# M55M1 register map
File version: 1.0
Registers are 32-bit, read-write, reset 0x0 unless marked. A register's access mark holds for its fields unless they carry their own. Offsets are from the block's base; [hi:lo] are bit positions; {n}, {i} and the like mark numbered series; 'fields as' and 'values as' point back to an identical list.

## LPI2C0 — LPI2C Register Map
Base 0x40443000
Same registers: LPI2C0_NS 0x50443000
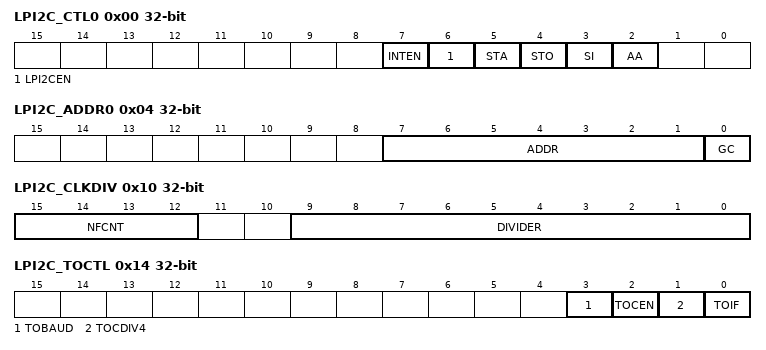
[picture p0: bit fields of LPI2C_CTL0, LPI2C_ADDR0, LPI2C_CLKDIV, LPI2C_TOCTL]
0x00 LPI2C_CTL0 — LPI2C Control Register 0
  [7] INTEN — Enable Interrupt
    0=LPI2C interrupt Disabled; 1=LPI2C interrupt Enabled
  [6] LPI2CEN — LPI2C Controller Enable Bit
    0=LPI2C controller Disabled; 1=LPI2C controller Enabled
  [5] STA — LPI2C START Control. Setting STA to logic 1 to enter Master mode, the LPI2C hardware sends a START or repeat START condition to bus when the bus is free. This bit will be cleared by hardware automatically.
  [4] STO — LPI2C STOP Control. In Master mode, set STO to transmit a STOP condition to bus then LPI2C controller will check the bus condition if a STOP condition is detected. This bit will be cleared by hardware automatically.
  [3] SI — LPI2C Interrupt Flag. When a new LPI2C state is present in the LPI2C_STATUS0 register, the SI flag is set by hardware. If bit INTEN (LPI2C_CTL0 [7]) is set, the LPI2C interrupt is requested. SI must be cleared by software. Clear SI by writing 1 to this bit.
  [2] AA — Assert Acknowledge Control
0x04 LPI2C_ADDR0 — LPI2C Slave Address Register0
  [7:1] ADDR — LPI2C Address. The content of this register is irrelevant when LPI2C is in Master mode. In the slave mode, the seven most significant bits must be loaded with the chip's own address. The LPI2C hardware will react if either of the address is matched. Note: When software set 7'h000, the address cannot be used.
  [0] GC — General Call Function
    0=General Call Function Disabled; 1=General Call Function Enabled
0x08 LPI2C_DAT — LPI2C Data Register
  [7:0] DAT — LPI2C Data. Bit [7:0] is located with the 8-bit transferred/received data of LPI2C serial port.
0x0C LPI2C_STATUS0 ro reset 0xF8 — LPI2C Status Register 0
  [7:0] STATUS — LPI2C Status
0x10 LPI2C_CLKDIV — LPI2C Clock Divided Register
  [15:12] NFCNT — Noise Filter Count. The register bits control the input filter width. If the pulse width is narrower than the setting((3+N)*PCLK), it will be ignored. Note: Filter width Min :3*PCLK, Max : 18*PCLK
    0=Filter width 3*PCLK; 1=Filter width 4*PCLK
  [9:0] DIVIDER — LPI2C Clock Divider. Note: The minimum value of DIVIDER is 4.
0x14 LPI2C_TOCTL — LPI2C Time-out Control Register
  [3] TOBAUD — Time-out Counter Input Clock Using Baud Rate Frequency. When enabled, the time-out counter is using baud rate.
    0=Time-out counter is using PCLK or PCLK/4; 1=Time-out counter is using IC baud rate
  [2] TOCEN — Time-out Counter Enable Bit. When enabled, the 14-bit time-out counter will start counting when SI is cleared. Setting flag SI to '1' will reset counter and re-start up counting after SI is cleared.
    0=Time-out counter Disabled; 1=Time-out counter Enabled
  [1] TOCDIV4 — Time-out Counter Input Clock Divided by 4. When enabled, the time-out period is extended 4 times. Note: This bit only worked when LPI2C_TOCTL[3] is set to 0.
    0=Time-out period is extend 4 times Disabled; 1=Time-out period is extend 4 times Enabled
  [0] TOIF — Time-out Flag. This bit is set by hardware when LPI2C time-out happened and it can interrupt CPU if LPI2C interrupt enable bit (INTEN) is set to 1. Note: Software can write 1 to clear this bit.
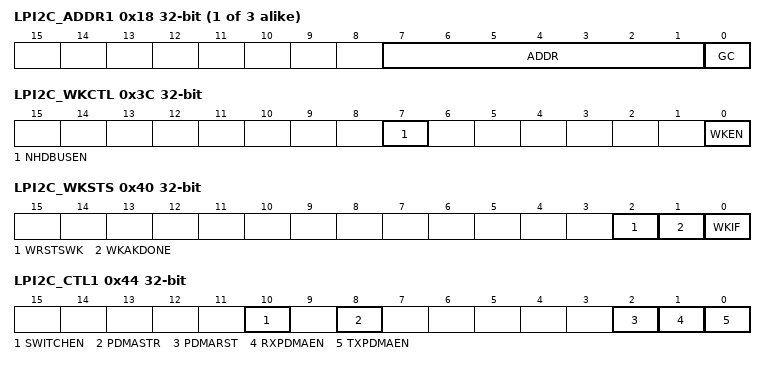
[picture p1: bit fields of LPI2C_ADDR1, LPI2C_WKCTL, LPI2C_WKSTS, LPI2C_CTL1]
{0x14+4i} LPI2C_ADDR{i} (i=1..3) — LPI2C Slave Address Register{i}
  fields as LPI2C_ADDR0
{0x24+4i} LPI2C_ADDRMSK{i} (i=0..3) — LPI2C Slave Address Mask Register{i}
  [7:1] ADDRMSK — LPI2C Address Mask. LPI2C bus controllers support multiple address recognition with four address mask register. When the bit in the address mask register is set to one, it means the received corresponding address bit is don't-care. If the bit is set to zero, that means the received corresponding register bit should be exact the same as address register.
    0=Mask Disabled (the received corresponding register bit should be exact the same as address register.); 1=Mask Enabled (the received corresponding address bit is don't care.)
0x3C LPI2C_WKCTL — LPI2C Wake-up Control Register
  [7] NHDBUSEN — LPI2C No Hold BUS Enable Bit. Note: The LPI2C controller could respond when WKIF event is not clear, it may cause error data transmitted or received. If data transmitted or received when WKIF event is not clear, user must reset LPI2C controller and execute the original operation again.
    0=LPI2C hold bus after wake-up; 1=LPI2C don't hold bus after wake-up
  [0] WKEN — LPI2C Wake-up Enable Bit. Note: This is for slave address match wakeup.
    0=LPI2C wake-up function Disabled; 1=LPI2C wake-up function Enabled
0x40 LPI2C_WKSTS — LPI2C Wake-up Status Register
  [2] WRSTSWK — Read/Write Status Bit in Address Wakeup Frame. Note: This bit will be cleared when software can write 1 to WKAKDONE bit.
    0=Write command be record on the address match wakeup frame; 1=Read command be record on the address match wakeup frame
  [1] WKAKDONE — Wakeup Address Frame Acknowledge Bit Done. Note: This bit can't release WKIF. Software can write 1 to clear this bit.
    0=The ACK bit cycle of address match frame isn't done; 1=The ACK bit cycle of address match frame is done in power-down
  [0] WKIF — LPI2C Wake-up Flag. When chip is woken up from Power-down mode by LPI2C, this bit is set to 1. Software can write 1 to clear this bit.
0x44 LPI2C_CTL1 — LPI2C Control Register 1
  [10] SWITCHEN — SCL And SDA Pin Switch Enable Bit. Note: Original pin configuration table is shown in Basic Configuration chapter.
    0=LPIC use original pin configuration; 1=LPIC switch SCL and SDA pin configuration
  [8] PDMASTR — LPPDMA Stretch Bit
    0=LPI2C send STOP automatically after LPPDMA transfer done. (only master TX); 1=LPI2C SCL bus is stretched by hardware after LPPDMA transfer done if the SI is not cleared. (only master TX)
  [2] PDMARST — LPPDMA Reset
    0=No effect; 1=Reset the LPI2C request to LPPDMA
  [1] RXPDMAEN — LPPDMA Receive Channel Available
    0=Receive LPPDMA function Disabled; 1=Receive LPPDMA function Enabled
  [0] TXPDMAEN — LPPDMA Transmit Channel Available
    0=Transmit LPPDMA function Disabled; 1=Transmit LPPDMA function Enabled
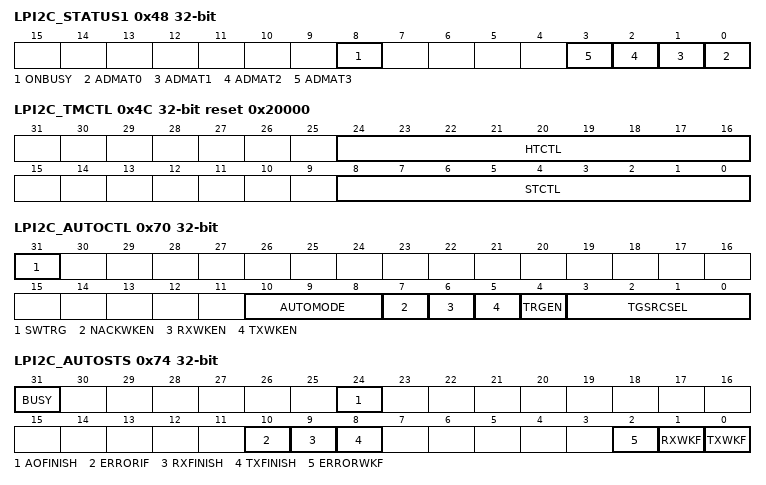
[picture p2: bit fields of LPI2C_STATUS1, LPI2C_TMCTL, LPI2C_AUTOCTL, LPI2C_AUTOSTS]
0x48 LPI2C_STATUS1 — LPI2C Status Register 1
  [8] ONBUSY ro — On Bus Busy (Read Only). Indicates that a communication is in progress on the bus. It is set by hardware when a START condition is detected. It is cleared by hardware when a STOP condition is detected.
    0=The bus is IDLE (both SCL and SDA High); 1=The bus is busy
  [n] ADMAT{n} (n=0..3) — LPI2C Address {n} Match Status. When address {n} is matched, hardware will inform which address used. This bit will set to 1, and software can write 1 to clear this bit.
0x4C LPI2C_TMCTL reset 0x20000 — LPI2C Timing Configure Control Register
  [24:16] HTCTL — Hold Time Configure Control. This field is used to generate the delay timing between SCL falling edge and SDA rising edge in transmission mode.
  [8:0] STCTL — Setup Time Configure Control. This field is used to generate a delay timing between SDA falling edge and SCL rising edge in transmission mode. Note: Setup time setting should not make SCL output less than three PCLKs.
0x70 LPI2C_AUTOCTL — LPI2C Automatic Operation Control Register
  [31] SWTRG — Auto-operation Mode Software Trigger Bit. Note: TGSRCSEL(LPI2C_AUTOCTL[3:0]) need to be set to 0x8 first. This bit will be cleared by hardware automatically.
    0=No operation; 1=Software trigger auto-operattion
  [10:8] AUTOMODE — Auto-operation Mode Select. Note: Use TXWKEN(LPI2C_AUTOCTL[5]) to wakeup system when using auto TXPDMA transfer mode AUTOMODE(LPI2C_AUTOCTL[10:8]) in power-down mode.
    0=No auto-operation; 1=Auto TXPDMA transfer mode; 2=Auto RXPDMA transfer mode; 3=Random Read mode, repeat start between TX/RX; 4=Random Read mode, stop and start between TX/RX
  [7] NACKWKEN — Receive Slave NACK Wakeup Enable bit
    0=Stop after receiving NACK; 1=Wakeup after receiving NACK
  [6] RXWKEN — RX Transfer Count Match Wakeup Enable bit
    0=Power off after RX transfer count matches RXCNT; 1=Wakeup after RX transfer count matches RXCNT
  [5] TXWKEN — TX Transfer Count Match Wakeup Enable bit
    0=Power off after TX transfer count matches TXCNT; 1=Wakeup after TX transfer count matches TXCNT
  [4] TRGEN — Trigger Source Enable bit
    0=LPIC trigger source disable; 1=LPIC trigger source enable
  [3:0] TGSRCSEL — Low Power Auto-operation Trigger Source Select
    0=Low Power Auto-operation Trigger Source from LPTMR0; 1=Low Power Auto-operation Trigger Source from LPTMR1; 2=Low Power Auto-operation Trigger Source from TTMR0; 3=Low Power Auto-operation Trigger Source from TTMR1; 4=Low Power Auto-operation Trigger Source from WKIOA0(GPA0); 5=Low Power Auto-operation Trigger Source from WKIOB0(GPB0); 6=Low Power Auto-operation Trigger Source from WKIOC0(GPC0); 7=Low Power Auto-operation Trigger Source from WKIOD0(GPD0); 8=Low Power Auto-operation Trigger Source from Software setting SWTRG(LPI2C_AUTOCTL[31]) to 1
0x74 LPI2C_AUTOSTS — LPI2C Automatic Operation Status Register
  [31] BUSY — Busy Flag. When chip is woken up and this bit is set to 1. It means that there were one or more requests from trigger source during transfer. Software can write 1 to clear this bit.
  [24] AOFINISH — Automatic Operation Finish Flag. AOFINISH is set when finishing one round of auto operation, but it will not issue interrupt. Software can write 1 to clear this bit.
  [10] ERRORIF — ERROR Interrupt Flag. When LPI2C receiving NACK from slave, running into bus error or arbitration lost, this bit is set to 1. Software can write 1 to clear this bit.
  [9] RXFINISH — Automatic Operation RX Finish Flag
  [8] TXFINISH — Automatic Operation TX Finish Flag
  [2] ERRORWKF — Error Condition Wakeup Flag. When chip is woken up from Power-down mode by LPI2C receiving NACK from slave, running into bus error or arbitration lost, this bit is set to 1. Software can write 1 to clear this bit.
  [1] RXWKF — RX Transfer Count Match Wakeup Flag. When chip is woken up from Power-down mode by LPI2C RX transfer count match, this bit is set to 1. Software can write 1 to clear this bit.
  [0] TXWKF — TX Transfer Count Match Wakeup Flag. When chip is woken up from Power-down mode by LPI2C TX transfer count match, this bit is set to 1. Software can write 1 to clear this bit.
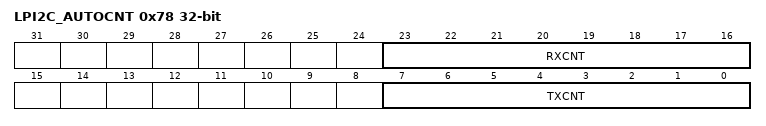
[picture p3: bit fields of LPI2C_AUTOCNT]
0x78 LPI2C_AUTOCNT — LPI2C Automatic Operation Transfer Count Register
  [23:16] RXCNT — RX Transfer Count. Bit [23:16] is set for RXPDMA and Random Read transfer mode. RXCNT represents the required number of the transfer, the real transfer count is RXCNT + 1. The maximum transfer count is 255 + 1. Note: RXCNT must be set at 1 or above when AUTOMODE (LPI2C_AUTOCTL[10:8]) is 3'b011 or 3'b100
  [7:0] TXCNT — TX Transfer Count. Bit [7:0] is set for TXPDMA and Random Read transfer mode. TXCNT represents the required number of the transfer, the real transfer count is TXCNT + 1. The maximum transfer count is 255 + 1.
